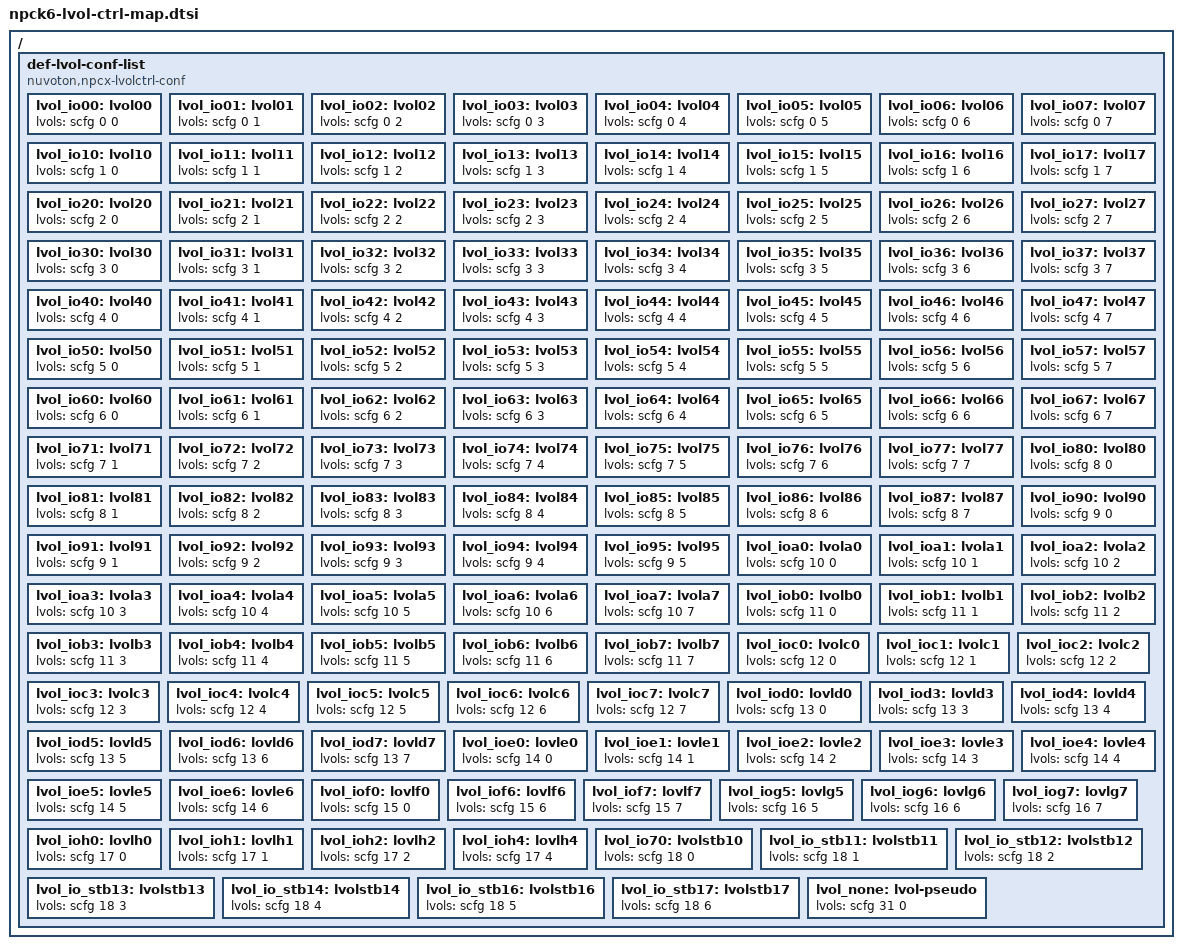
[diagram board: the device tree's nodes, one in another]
/*
 * Copyright (c) 2026 Nuvoton Technology Corporation.
 *
 * SPDX-License-Identifier: Apache-2.0
 */

/* Common Low-Voltage level configurations in npck */
#include <nuvoton/npck/npck-lvol-ctrl-map.dtsi>

/* Specific Low-Voltage level configurations in npck6 series */
/ {
	def-lvol-conf-list {
		compatible = "nuvoton,npcx-lvolctrl-conf";

		/* Low-Voltage IO Control 0 */
		lvol_io00: lvol00 {
			lvols = <&scfg 0 0>;
		};

		lvol_io01: lvol01 {
			lvols = <&scfg 0 1>;
		};

		lvol_io02: lvol02 {
			lvols = <&scfg 0 2>;
		};

		lvol_io03: lvol03 {
			lvols = <&scfg 0 3>;
		};

		lvol_io04: lvol04 {
			lvols = <&scfg 0 4>;
		};

		lvol_io05: lvol05 {
			lvols = <&scfg 0 5>;
		};

		lvol_io06: lvol06 {
			lvols = <&scfg 0 6>;
		};

		lvol_io07: lvol07 {
			lvols = <&scfg 0 7>;
		};

		/* Low-Voltage IO Control 1 */
		lvol_io10: lvol10 {
			lvols = <&scfg 1 0>;
		};

		lvol_io11: lvol11 {
			lvols = <&scfg 1 1>;
		};

		lvol_io12: lvol12 {
			lvols = <&scfg 1 2>;
		};

		lvol_io13: lvol13 {
			lvols = <&scfg 1 3>;
		};

		lvol_io14: lvol14 {
			lvols = <&scfg 1 4>;
		};

		lvol_io15: lvol15 {
			lvols = <&scfg 1 5>;
		};

		lvol_io16: lvol16 {
			lvols = <&scfg 1 6>;
		};

		lvol_io17: lvol17 {
			lvols = <&scfg 1 7>;
		};

		/* Low-Voltage IO Control 2 */
		lvol_io20: lvol20 {
			lvols = <&scfg 2 0>;
		};

		lvol_io21: lvol21 {
			lvols = <&scfg 2 1>;
		};

		lvol_io22: lvol22 {
			lvols = <&scfg 2 2>;
		};

		lvol_io23: lvol23 {
			lvols = <&scfg 2 3>;
		};

		lvol_io24: lvol24 {
			lvols = <&scfg 2 4>;
		};

		lvol_io25: lvol25 {
			lvols = <&scfg 2 5>;
		};

		lvol_io26: lvol26 {
			lvols = <&scfg 2 6>;
		};

		lvol_io27: lvol27 {
			lvols = <&scfg 2 7>;
		};

		/* Low-Voltage IO Control 3 */
		lvol_io30: lvol30 {
			lvols = <&scfg 3 0>;
		};

		lvol_io31: lvol31 {
			lvols = <&scfg 3 1>;
		};

		lvol_io32: lvol32 {
			lvols = <&scfg 3 2>;
		};

		lvol_io33: lvol33 {
			lvols = <&scfg 3 3>;
		};

		lvol_io34: lvol34 {
			lvols = <&scfg 3 4>;
		};

		lvol_io35: lvol35 {
			lvols = <&scfg 3 5>;
		};

		lvol_io36: lvol36 {
			lvols = <&scfg 3 6>;
		};

		lvol_io37: lvol37 {
			lvols = <&scfg 3 7>;
		};

		/* Low-Voltage IO Control 4 */
		lvol_io40: lvol40 {
			lvols = <&scfg 4 0>;
		};

		lvol_io41: lvol41 {
			lvols = <&scfg 4 1>;
		};

		lvol_io42: lvol42 {
			lvols = <&scfg 4 2>;
		};

		lvol_io43: lvol43 {
			lvols = <&scfg 4 3>;
		};

		lvol_io44: lvol44 {
			lvols = <&scfg 4 4>;
		};

		lvol_io45: lvol45 {
			lvols = <&scfg 4 5>;
		};

		lvol_io46: lvol46 {
			lvols = <&scfg 4 6>;
		};

		lvol_io47: lvol47 {
			lvols = <&scfg 4 7>;
		};

		/* Low-Voltage IO Control 5 */
		lvol_io50: lvol50 {
			lvols = <&scfg 5 0>;
		};

		lvol_io51: lvol51 {
			lvols = <&scfg 5 1>;
		};

		lvol_io52: lvol52 {
			lvols = <&scfg 5 2>;
		};

		lvol_io53: lvol53 {
			lvols = <&scfg 5 3>;
		};

		lvol_io54: lvol54 {
			lvols = <&scfg 5 4>;
		};

		lvol_io55: lvol55 {
			lvols = <&scfg 5 5>;
		};

		lvol_io56: lvol56 {
			lvols = <&scfg 5 6>;
		};

		lvol_io57: lvol57 {
			lvols = <&scfg 5 7>;
		};

		/* Low-Voltage IO Control 6 */
		lvol_io60: lvol60 {
			lvols = <&scfg 6 0>;
		};

		lvol_io61: lvol61 {
			lvols = <&scfg 6 1>;
		};

		lvol_io62: lvol62 {
			lvols = <&scfg 6 2>;
		};

		lvol_io63: lvol63 {
			lvols = <&scfg 6 3>;
		};

		lvol_io64: lvol64 {
			lvols = <&scfg 6 4>;
		};

		lvol_io65: lvol65 {
			lvols = <&scfg 6 5>;
		};

		lvol_io66: lvol66 {
			lvols = <&scfg 6 6>;
		};

		lvol_io67: lvol67 {
			lvols = <&scfg 6 7>;
		};

		/* Low-Voltage IO Control 7 */
		lvol_io71: lvol71 {
			lvols = <&scfg 7 1>;
		};

		lvol_io72: lvol72 {
			lvols = <&scfg 7 2>;
		};

		lvol_io73: lvol73 {
			lvols = <&scfg 7 3>;
		};

		lvol_io74: lvol74 {
			lvols = <&scfg 7 4>;
		};

		lvol_io75: lvol75 {
			lvols = <&scfg 7 5>;
		};

		lvol_io76: lvol76 {
			lvols = <&scfg 7 6>;
		};

		lvol_io77: lvol77 {
			lvols = <&scfg 7 7>;
		};

		/* Low-Voltage IO Control 8 */
		lvol_io80: lvol80 {
			lvols = <&scfg 8 0>;
		};

		lvol_io81: lvol81 {
			lvols = <&scfg 8 1>;
		};

		lvol_io82: lvol82 {
			lvols = <&scfg 8 2>;
		};

		lvol_io83: lvol83 {
			lvols = <&scfg 8 3>;
		};

		lvol_io84: lvol84 {
			lvols = <&scfg 8 4>;
		};

		lvol_io85: lvol85 {
			lvols = <&scfg 8 5>;
		};

		lvol_io86: lvol86 {
			lvols = <&scfg 8 6>;
		};

		lvol_io87: lvol87 {
			lvols = <&scfg 8 7>;
		};

		/* Low-Voltage IO Control 9 */
		lvol_io90: lvol90 {
			lvols = <&scfg 9 0>;
		};

		lvol_io91: lvol91 {
			lvols = <&scfg 9 1>;
		};

		lvol_io92: lvol92 {
			lvols = <&scfg 9 2>;
		};

		lvol_io93: lvol93 {
			lvols = <&scfg 9 3>;
		};

		lvol_io94: lvol94 {
			lvols = <&scfg 9 4>;
		};

		lvol_io95: lvol95 {
			lvols = <&scfg 9 5>;
		};

		/* Low-Voltage IO Control A */
		lvol_ioa0: lvola0 {
			lvols = <&scfg 10 0>;
		};

		lvol_ioa1: lvola1 {
			lvols = <&scfg 10 1>;
		};

		lvol_ioa2: lvola2 {
			lvols = <&scfg 10 2>;
		};

		lvol_ioa3: lvola3 {
			lvols = <&scfg 10 3>;
		};

		lvol_ioa4: lvola4 {
			lvols = <&scfg 10 4>;
		};

		lvol_ioa5: lvola5 {
			lvols = <&scfg 10 5>;
		};

		lvol_ioa6: lvola6 {
			lvols = <&scfg 10 6>;
		};

		lvol_ioa7: lvola7 {
			lvols = <&scfg 10 7>;
		};

		/* Low-Voltage IO Control B */

		lvol_iob0: lvolb0 {
			lvols = <&scfg 11 0>;
		};

		lvol_iob1: lvolb1 {
			lvols = <&scfg 11 1>;
		};

		lvol_iob2: lvolb2 {
			lvols = <&scfg 11 2>;
		};

		lvol_iob3: lvolb3 {
			lvols = <&scfg 11 3>;
		};

		lvol_iob4: lvolb4 {
			lvols = <&scfg 11 4>;
		};

		lvol_iob5: lvolb5 {
			lvols = <&scfg 11 5>;
		};

		lvol_iob6: lvolb6 {
			lvols = <&scfg 11 6>;
		};

		lvol_iob7: lvolb7 {
			lvols = <&scfg 11 7>;
		};

		/* Low-Voltage IO Control C */
		lvol_ioc0: lvolc0 {
			lvols = <&scfg 12 0>;
		};

		lvol_ioc1: lvolc1 {
			lvols = <&scfg 12 1>;
		};

		lvol_ioc2: lvolc2 {
			lvols = <&scfg 12 2>;
		};

		lvol_ioc3: lvolc3 {
			lvols = <&scfg 12 3>;
		};

		lvol_ioc4: lvolc4 {
			lvols = <&scfg 12 4>;
		};

		lvol_ioc5: lvolc5 {
			lvols = <&scfg 12 5>;
		};

		lvol_ioc6: lvolc6 {
			lvols = <&scfg 12 6>;
		};

		lvol_ioc7: lvolc7 {
			lvols = <&scfg 12 7>;
		};

		/* Low-Voltage IO Control D */
		lvol_iod0: lovld0 {
			lvols = <&scfg 13 0>;
		};

		lvol_iod3: lovld3 {
			lvols = <&scfg 13 3>;
		};

		lvol_iod4: lovld4 {
			lvols = <&scfg 13 4>;
		};

		lvol_iod5: lovld5 {
			lvols = <&scfg 13 5>;
		};

		lvol_iod6: lovld6 {
			lvols = <&scfg 13 6>;
		};

		lvol_iod7: lovld7 {
			lvols = <&scfg 13 7>;
		};

		/* Low-Voltage IO Control E */
		lvol_ioe0: lovle0 {
			lvols = <&scfg 14 0>;
		};

		lvol_ioe1: lovle1 {
			lvols = <&scfg 14 1>;
		};

		lvol_ioe2: lovle2 {
			lvols = <&scfg 14 2>;
		};

		lvol_ioe3: lovle3 {
			lvols = <&scfg 14 3>;
		};

		lvol_ioe4: lovle4 {
			lvols = <&scfg 14 4>;
		};

		lvol_ioe5: lovle5 {
			lvols = <&scfg 14 5>;
		};

		lvol_ioe6: lovle6 {
			lvols = <&scfg 14 6>;
		};

		/* Low-Voltage IO Control F */
		lvol_iof0: lovlf0 {
			lvols = <&scfg 15 0>;
		};

		lvol_iof6: lovlf6 {
			lvols = <&scfg 15 6>;
		};

		lvol_iof7: lovlf7 {
			lvols = <&scfg 15 7>;
		};

		/* Low-Voltage IO Control 10 */
		lvol_iog5: lovlg5 {
			lvols = <&scfg 16 5>;
		};

		lvol_iog6: lovlg6 {
			lvols = <&scfg 16 6>;
		};

		lvol_iog7: lovlg7 {
			lvols = <&scfg 16 7>;
		};

		/* Low-Voltage IO Control 11 */
		lvol_ioh0: lovlh0 {
			lvols = <&scfg 17 0>;
		};

		lvol_ioh1: lovlh1 {
			lvols = <&scfg 17 1>;
		};

		lvol_ioh2: lovlh2 {
			lvols = <&scfg 17 2>;
		};

		lvol_ioh4: lovlh4 {
			lvols = <&scfg 17 4>;
		};

		/* Low-Voltage IO Control 12 */
		lvol_io70: lvolstb10 {
			lvols = <&scfg 18 0>;
		};

		lvol_io_stb11: lvolstb11 {
			lvols = <&scfg 18 1>;
		};

		lvol_io_stb12: lvolstb12 {
			lvols = <&scfg 18 2>;
		};

		lvol_io_stb13: lvolstb13 {
			lvols = <&scfg 18 3>;
		};

		lvol_io_stb14: lvolstb14 {
			lvols = <&scfg 18 4>;
		};

		lvol_io_stb16: lvolstb16 {
			lvols = <&scfg 18 5>;
		};

		lvol_io_stb17: lvolstb17 {
			lvols = <&scfg 18 6>;
		};

		/*
		 * Pseudo Low-Voltage IO Control (i.e. IO pad doesn't support
		 * low voltage detection.)
		 */
		lvol_none: lvol-pseudo {
			lvols = <&scfg 31 0>;
		};
	};
};
